VERSION ""

NS_ :

BS_:
BU_: DME_Etc
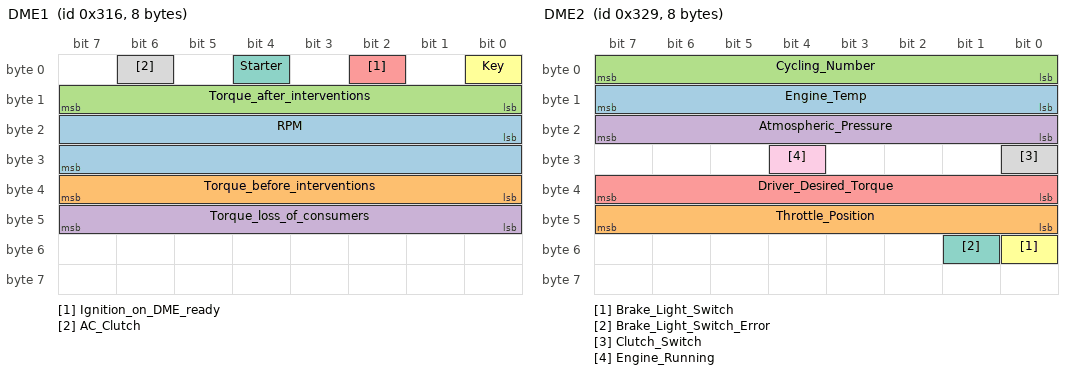
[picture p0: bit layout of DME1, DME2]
BO_ 790 DME1: 8 DME_Etc
   SG_ RPM : 16|16@1+ (0.156,0) [0|0] "" DME_Etc
   SG_ Torque_before_interventions : 32|8@1+ (1,0) [0|0] "" DME_Etc
   SG_ Torque_after_interventions : 8|8@1+ (1,0) [0|0] "" Vector__XXX
   SG_ Torque_loss_of_consumers : 40|8@1+ (1,0) [0|0] "" DME_Etc
   SG_ Ignition_on_DME_ready : 2|1@1+ (1,0) [0|0] "" DME_Etc
   SG_ Key : 0|1@1+ (1,0) [0|0] "" Vector__XXX
   SG_ Starter : 4|1@1+ (1,0) [0|0] "" Vector__XXX
   SG_ AC_Clutch : 6|1@1+ (1,0) [0|0] "" Vector__XXX

BO_ 809 DME2: 8 DME_Etc
   SG_ Engine_Temp : 8|8@1+ (0.75,-48.373) [0|0] "deg_c" DME_Etc
   SG_ Throttle_Position : 40|8@1+ (1,0) [0|0] "%" DME_Etc
   SG_ Cycling_Number : 0|8@1+ (1,0) [0|0] "" DME_Etc
   SG_ Atmospheric_Pressure : 16|8@1+ (2,597) [0|0] "mbar" DME_Etc
   SG_ Driver_Desired_Torque : 32|8@1+ (1,0) [0|0] "" DME_Etc
   SG_ Brake_Light_Switch : 48|1@1+ (1,0) [0|0] "" DME_Etc
   SG_ Brake_Light_Switch_Error : 49|1@1+ (1,0) [0|0] "" Vector__XXX
   SG_ Clutch_Switch : 24|1@1+ (1,0) [0|0] "" Vector__XXX
   SG_ Engine_Running : 28|1@1+ (1,0) [0|0] "" Vector__XXX

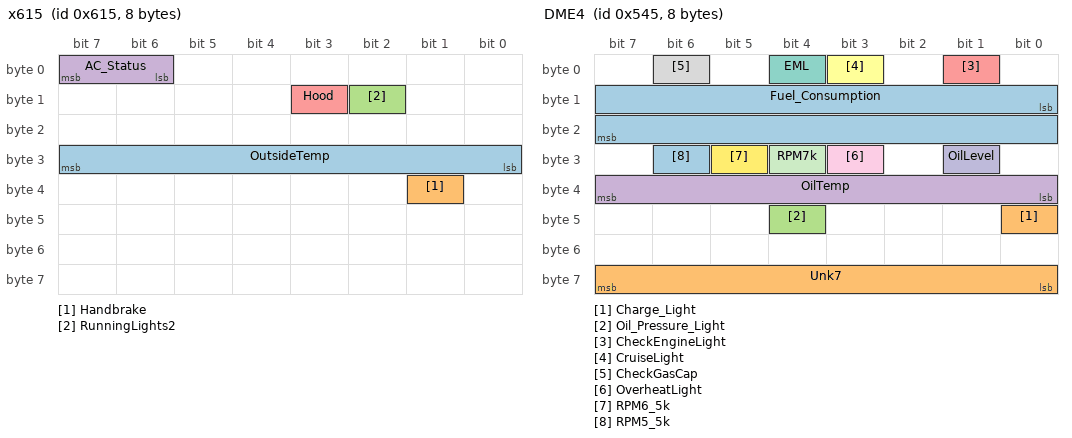
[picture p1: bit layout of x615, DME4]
BO_ 1557 x615: 8 DME_Etc
   SG_ OutsideTemp : 24|8@1- (1,0) [0|0] "deg_c" DME_Etc
   SG_ Handbrake : 33|1@0+ (1,0) [0|1] "" Vector__XXX
   SG_ RunningLights2 : 10|1@0+ (1,0) [0|1] "" Vector__XXX
   SG_ AC_Status : 6|2@1+ (1,0) [0|1] "" Vector__XXX
   SG_ Hood : 11|1@0+ (1,0) [0|1] "" Vector__XXX

BO_ 1349 DME4: 8 DME_Etc
   SG_ Fuel_Consumption : 8|16@1+ (1,0) [0|0] "mpg" DME_Etc
   SG_ Charge_Light : 40|1@1+ (1,0) [0|0] "" Vector__XXX
   SG_ Oil_Pressure_Light : 44|1@1+ (1,0) [0|0] "" DME_Etc
   SG_ OilTemp : 32|8@1+ (1,-48.373) [0|0] "deg_c" DME_Etc
   SG_ CheckEngineLight : 1|1@1+ (1,0) [0|0] "" Vector__XXX
   SG_ CruiseLight : 3|1@1+ (1,0) [0|0] "" Vector__XXX
   SG_ EML : 4|1@1+ (1,0) [0|0] "" Vector__XXX
   SG_ CheckGasCap : 6|1@1+ (1,0) [0|0] "" Vector__XXX
   SG_ OverheatLight : 27|1@1+ (1,0) [0|0] "" DME_Etc
   SG_ OilLevel : 25|1@1+ (1,0) [0|0] "" DME_Etc
   SG_ RPM7k : 28|1@1+ (1,0) [0|0] "" DME_Etc
   SG_ RPM6_5k : 29|1@1+ (1,0) [0|0] "" DME_Etc
   SG_ RPM5_5k : 30|1@1+ (1,0) [0|0] "" DME_Etc
   SG_ Unk7 : 56|8@1+ (1,0) [0|0] "" DME_Etc

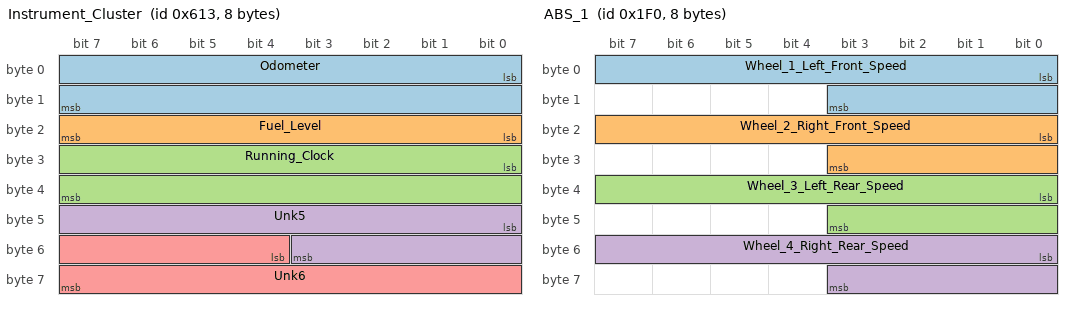
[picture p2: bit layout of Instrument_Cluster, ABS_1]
BO_ 1555 Instrument_Cluster: 8 DME_Etc
   SG_ Odometer : 0|16@1+ (10,0) [0|0] "" DME_Etc
   SG_ Fuel_Level : 16|8@1+ (1,0) [0|0] "" DME_Etc
   SG_ Running_Clock : 24|16@1+ (1,0) [0|0] "Seconds" DME_Etc
   SG_ Unk5 : 40|12@1+ (1,0) [0|1] "" Vector__XXX
   SG_ Unk6 : 52|12@1+ (1,0) [0|1] "" Vector__XXX

BO_ 496 ABS_1: 8 DME_Etc
   SG_ Wheel_1_Left_Front_Speed : 0|12@1+ (0.0625,0) [0|0] "" Vector__XXX
   SG_ Wheel_2_Right_Front_Speed : 16|12@1+ (0.0625,0) [0|0] "" DME_Etc
   SG_ Wheel_3_Left_Rear_Speed : 32|12@1+ (0.0625,0) [0|0] "" DME_Etc
   SG_ Wheel_4_Right_Rear_Speed : 48|12@1+ (0.0625,0) [0|0] "" Vector__XXX

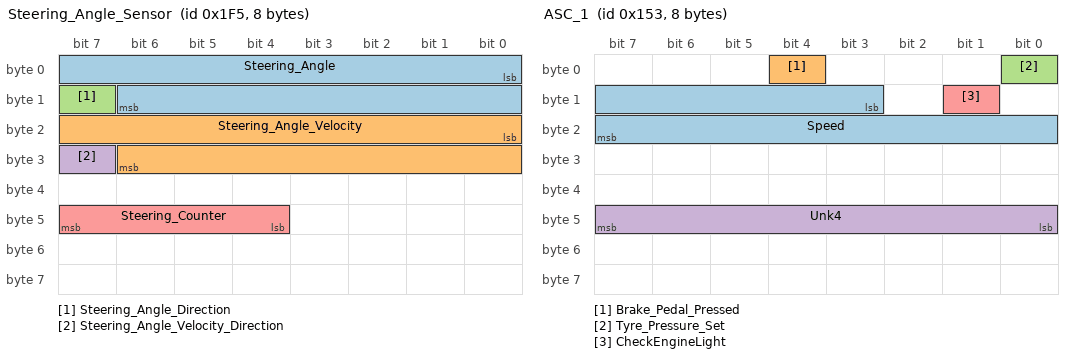
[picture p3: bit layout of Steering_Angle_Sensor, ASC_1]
BO_ 501 Steering_Angle_Sensor: 8 DME_Etc
   SG_ Steering_Angle : 0|15@1+ (0.045,0) [0|0] "" DME_Etc
   SG_ Steering_Angle_Velocity : 16|15@1+ (0.045,0) [0|0] "" DME_Etc
   SG_ Steering_Angle_Direction : 15|1@1+ (1,0) [0|0] "" Vector__XXX
   SG_ Steering_Angle_Velocity_Direction : 31|1@1+ (1,0) [0|0] "" Vector__XXX
   SG_ Steering_Counter : 44|4@1+ (1,0) [0|0] "" Vector__XXX

BO_ 339 ASC_1: 8 DME_Etc
   SG_ Speed : 11|13@1+ (0.0625,0) [0|0] "" DME_Etc
   SG_ Brake_Pedal_Pressed : 4|1@1+ (1,0) [0|0] "" Vector__XXX
   SG_ Tyre_Pressure_Set : 0|1@1+ (1,0) [0|0] "" Vector__XXX
   SG_ Unk4 : 40|8@1+ (1,0) [0|0] "" Vector__XXX
   SG_ CheckEngineLight : 9|1@1+ (1,0) [0|0] "" Vector__XXX

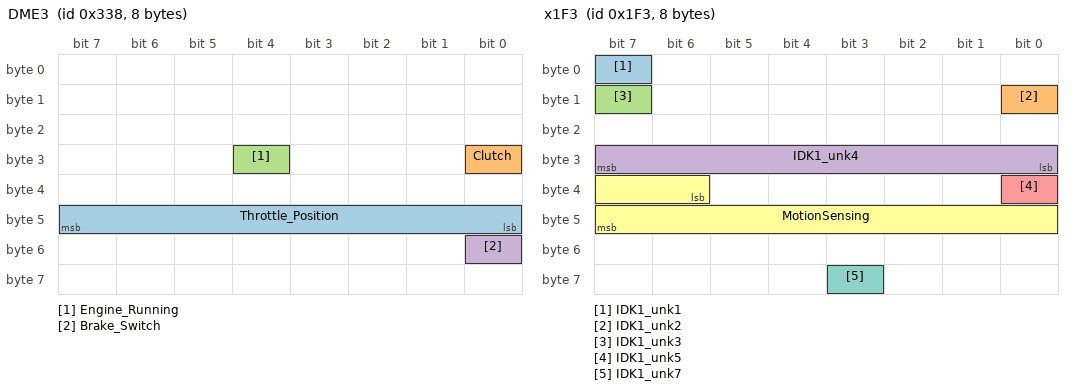
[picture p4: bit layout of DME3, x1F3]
BO_ 824 DME3: 8 DME_Etc
   SG_ Throttle_Position : 40|8@1+ (1,0) [0|0] "" DME_Etc
   SG_ Clutch : 24|1@1+ (1,0) [0|0] "" DME_Etc
   SG_ Engine_Running : 28|1@1+ (1,0) [0|0] "" DME_Etc
   SG_ Brake_Switch : 48|1@1+ (1,0) [0|0] "" Vector__XXX

BO_ 499 x1F3: 8 DME_Etc
   SG_ IDK1_unk1 : 7|1@1+ (1,0) [0|1] "" Vector__XXX
   SG_ IDK1_unk2 : 8|1@1+ (1,0) [0|1] "" Vector__XXX
   SG_ IDK1_unk3 : 15|1@1+ (1,0) [0|1] "" Vector__XXX
   SG_ IDK1_unk4 : 24|8@1+ (1,0) [0|255] "" Vector__XXX
   SG_ IDK1_unk5 : 32|1@1+ (1,0) [0|1] "" Vector__XXX
   SG_ MotionSensing : 38|10@1+ (1,0) [0|4] "" Vector__XXX
   SG_ IDK1_unk7 : 59|1@1+ (1,0) [0|0] "" Vector__XXX

BO_ 1381 x565: 8 DME_Etc
   SG_ IDK2_unk1 : 55|1@1+ (1,0) [0|1] "" Vector__XXX
   SG_ IDK2_unk2 : 6|1@1+ (1,0) [0|1] "" Vector__XXX
   SG_ IDK2_unk3 : 13|1@1+ (1,0) [0|1] "" Vector__XXX
   SG_ IDK2_unk4 : 16|8@1+ (1,0) [0|1] "" Vector__XXX
   SG_ IDK2_unk5 : 25|1@1+ (1,0) [0|1] "" Vector__XXX
   SG_ IDK2_unk6 : 41|1@1+ (1,0) [0|1] "" Vector__XXX
   SG_ Unk7 : 56|8@1+ (1,0) [0|1] "" Vector__XXX
   SG_ OilPressure : 48|8@1+ (2,0) [0|0] "mPa" Vector__XXX

BO_ 1560 x618: 8 DME_Etc
   SG_ IDK3unk2 : 16|8@1+ (1,0) [0|0] "" Vector__XXX

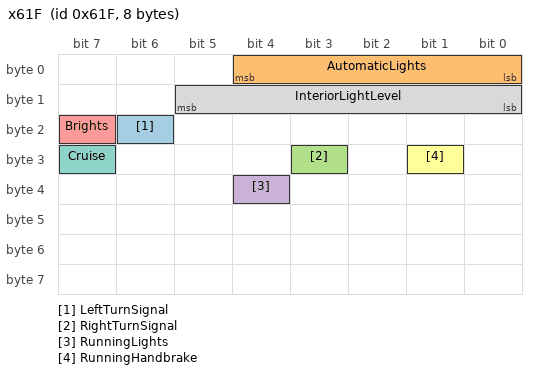
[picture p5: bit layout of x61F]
BO_ 1567 x61F: 8 DME_Etc
   SG_ LeftTurnSignal : 22|1@0+ (1,0) [0|1] "" Vector__XXX
   SG_ AutomaticLights : 0|5@1+ (1,0) [0|1] "" Vector__XXX
   SG_ RightTurnSignal : 27|1@1+ (1,0) [0|1] "" Vector__XXX
   SG_ RunningLights : 36|1@1+ (1,0) [0|1] "" Vector__XXX
   SG_ Brights : 23|1@0+ (1,0) [0|1] "" Vector__XXX
   SG_ RunningHandbrake : 25|1@0+ (1,0) [0|1] "" Vector__XXX
   SG_ Cruise : 31|1@0+ (1,0) [0|1] "" Vector__XXX
   SG_ InteriorLightLevel : 8|6@1+ (1,0) [0|1] "" Vector__XXX

BO_ 1562 x61A: 8 DME_Etc
   SG_ StalkState : 40|20@1+ (1,0) [0|1] "" Vector__XXX

BO_ 822 x336: 8 DME_Etc
   SG_ x336Sig347 : 0|64@1+ (1,0) [0|1] "" Vector__XXX

BO_ 504 x1F8: 8 DME_Etc
   SG_ BrakePressure : 16|8@1+ (1,0) [0|1] "" Vector__XXX

BO_ 1552 x610: 8 DME_Etc
   SG_ x610Sig39 : 0|64@1+ (1,0) [0|1] "" Vector__XXX

BO_ 1281 x501: 8 DME_Etc
   SG_ x501Sig34 : 0|64@1+ (1,0) [0|1] "" Vector__XXX

BA_DEF_ BO_ "GenMsgBackgroundColor" STRING ;
BA_DEF_ BO_ "GenMsgForegroundColor" STRING ;
BA_DEF_ BO_ "filterlabeling" INT 0 0;
BA_DEF_ BO_ "filterlabeling" INT 0 0;
BA_DEF_ BO_ "filterlabeling" INT 0 0;
BA_DEF_ BO_ "filterlabeling" INT 0 0;
BA_DEF_ BO_ "filterlabeling" INT 0 0;
BA_DEF_ BO_ "filterlabeling" INT 0 0;
BA_DEF_ BO_ "filterlabeling" INT 0 0;
BA_DEF_DEF_ "GenMsgBackgroundColor" "#ffffff";
BA_DEF_DEF_ "GenMsgForegroundColor" "#000000";
BA_DEF_DEF_ "filterlabeling" 0;
BA_DEF_DEF_ "filterlabeling" true;
VAL_ 790 Ignition_on_DME_ready 1 "On" 0 "Off";
VAL_ 790 Key 0 "Off" 1 "On";
VAL_ 790 Starter 0 "Off" 1 "On";
VAL_ 790 AC_Clutch 0 "Off" 1 "On";
VAL_ 809 Brake_Light_Switch 1 "Pressed" 0 "Not_Pressed";
VAL_ 809 Brake_Light_Switch_Error 0 "Off" 1 "Error";
VAL_ 809 Clutch_Switch 0 "Not_pressed" 1 "Pressed";
VAL_ 809 Engine_Running 0 "Not_running" 1 "Running";
VAL_ 1349 Charge_Light 0 "Off" 1 "On";
VAL_ 1349 Oil_Pressure_Light 0 "Off" 1 "On";
VAL_ 339 Brake_Pedal_Pressed 0 "Not_pressed" 1 "Pressed";
VAL_ 824 Clutch 0 "Not_pressed" 1 "Pressed";
VAL_ 824 Engine_Running 0 "Not_running" 1 "Running";
VAL_ 824 Brake_Switch 0 "Not_pressed" 1 "Pressed";
